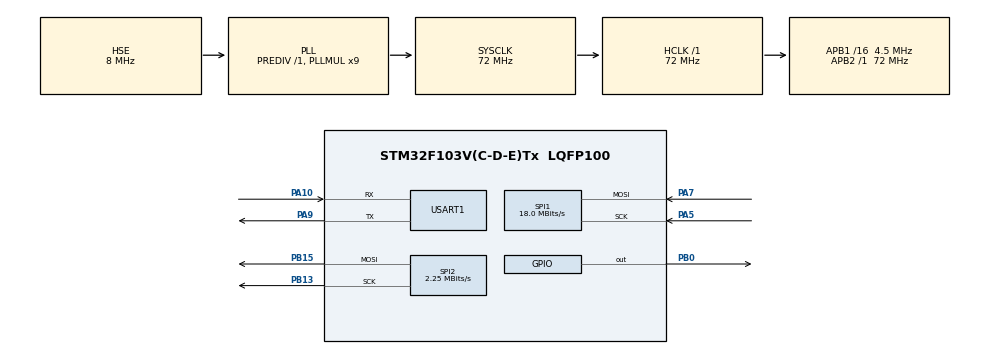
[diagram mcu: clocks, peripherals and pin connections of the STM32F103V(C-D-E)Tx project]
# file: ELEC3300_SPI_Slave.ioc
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Mcu.Family=STM32F1
Mcu.Name=STM32F103V(C-D-E)Tx
Mcu.Package=LQFP100
NVIC.PriorityGroup=NVIC_PRIORITYGROUP_4
OSC_IN.Mode=HSE-External-Oscillator
OSC_IN.Signal=RCC_OSC_IN
OSC_OUT.Mode=HSE-External-Oscillator
OSC_OUT.Signal=RCC_OSC_OUT
PA10.Mode=Asynchronous
PA10.Signal=USART1_RX
PA13.Mode=Serial_Wire
PA13.Signal=SYS_JTMS-SWDIO
PA14.Mode=Serial_Wire
PA14.Signal=SYS_JTCK-SWCLK
PA5.Mode=RX_Only_Simplex_Unidirect_Slave
PA5.Signal=SPI1_SCK
PA7.Mode=RX_Only_Simplex_Unidirect_Slave
PA7.Signal=SPI1_MOSI
PA9.Mode=Asynchronous
PA9.Signal=USART1_TX
PB0.GPIO_Speed=GPIO_SPEED_FREQ_HIGH
PB0.PinState=GPIO_PIN_SET
PB0.Signal=GPIO_Output
PB13.Mode=TX_Only_Simplex_Unidirect_Master
PB13.Signal=SPI2_SCK
PB15.Mode=TX_Only_Simplex_Unidirect_Master
PB15.Signal=SPI2_MOSI
PC14-OSC32_IN.Mode=LSE-External-Oscillator
PC14-OSC32_IN.Signal=RCC_OSC32_IN
PC15-OSC32_OUT.Mode=LSE-External-Oscillator
PC15-OSC32_OUT.Signal=RCC_OSC32_OUT
ProjectManager.HeapSize=0x200
ProjectManager.StackSize=0x400
ProjectManager.TargetToolchain=MDK-ARM V5.27
RCC.AHBFreq_Value=72000000
RCC.APB1CLKDivider=RCC_HCLK_DIV16
RCC.APB1Freq_Value=4500000
RCC.APB1TimFreq_Value=9000000
RCC.APB2Freq_Value=72000000
RCC.APB2TimFreq_Value=72000000
RCC.HCLKFreq_Value=72000000
RCC.PLLMUL=RCC_PLL_MUL9
RCC.PLLSourceVirtual=RCC_PLLSOURCE_HSE
RCC.SYSCLKFreq_VALUE=72000000
RCC.SYSCLKSource=RCC_SYSCLKSOURCE_PLLCLK
RCC.USBFreq_Value=72000000
SPI1.BaudRatePrescaler=SPI_BAUDRATEPRESCALER_4
SPI1.CalculateBaudRate=18.0 MBits/s
SPI1.Direction=SPI_DIRECTION_2LINES_RXONLY
SPI1.Mode=SPI_MODE_SLAVE
SPI1.VirtualType=VM_SLAVE
SPI2.CalculateBaudRate=2.25 MBits/s
SPI2.Direction=SPI_DIRECTION_2LINES
SPI2.Mode=SPI_MODE_MASTER
SPI2.VirtualType=VM_MASTER
USART1.VirtualMode=VM_ASYNC
board=custom

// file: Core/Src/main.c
/* USER CODE BEGIN Header */
/**
  ******************************************************************************
  * @file           : main.c
  * @brief          : Main program body
  ******************************************************************************
  * @attention
  *
  * <h2><center>&copy; Copyright (c) 2023 STMicroelectronics.
  * All rights reserved.</center></h2>
  *
  * This software component is licensed by ST under BSD 3-Clause license,
  * the "License"; You may not use this file except in compliance with the
  * License. You may obtain a copy of the License at:
  *                        opensource.org/licenses/BSD-3-Clause
  *
  ******************************************************************************
  */
/* USER CODE END Header */
#include "main.h"

SPI_HandleTypeDef hspi1;
SPI_HandleTypeDef hspi2;

UART_HandleTypeDef huart1;

void SystemClock_Config(void);
static void MX_GPIO_Init(void);
static void MX_SPI1_Init(void);
static void MX_USART1_UART_Init(void);
static void MX_SPI2_Init(void);

int main(void)
{
  /* USER CODE BEGIN 1 */
	uint8_t message_1[50] = "Now transmitting message back to NUCLEO-144\n";
	uint8_t data[27] = "ello World\n";
	uint8_t RX_Data[27] = {0};
  /* USER CODE END 1 */

  /* MCU Configuration--------------------------------------------------------*/

  /* Reset of all peripherals, Initializes the Flash interface and the Systick. */
  HAL_Init();

  /* Configure the system clock */
  SystemClock_Config();

  /* Initialize all configured peripherals */
  MX_GPIO_Init();
  MX_SPI1_Init();
  MX_USART1_UART_Init();
  MX_SPI2_Init();

  /* Infinite loop */
  while (1)
  {

    /* USER CODE BEGIN 3 */
		// Re-initialise rx_data every loop
		// We will receive data of 27 bytes (change this according to the data size being sent to slave)
		//uint8_t rx_data[27] = "No data received\n";
		//HAL_GPIO_WritePin(GPIOB, GPIO_PIN_0, GPIO_PIN_RESET);
		//HAL_Delay(100);
		//HAL_GPIO_WritePin(GPIOB, GPIO_PIN_0, GPIO_PIN_SET);
		//HAL_Delay(100);
		HAL_SPI_Transmit(&hspi2, data, 27, 5000);
		//HAL_Delay(5000);
		HAL_SPI_Receive(&hspi1, RX_Data, 27, 5000); // timing out -> if LED blink then wait for 5 secs, means receive nothing
		//HAL_Delay(5000);
		HAL_UART_Transmit(&huart1, RX_Data, 27, 5000);
		//HAL_Delay(1000);

  }
  /* USER CODE END 3 */
}

void SystemClock_Config(void)
{
  RCC_OscInitTypeDef RCC_OscInitStruct = {0};
  RCC_ClkInitTypeDef RCC_ClkInitStruct = {0};

  /** Initializes the RCC Oscillators according to the specified parameters
  * in the RCC_OscInitTypeDef structure.
  */
  RCC_OscInitStruct.OscillatorType = RCC_OSCILLATORTYPE_HSE;
  RCC_OscInitStruct.HSEState = RCC_HSE_ON;
  RCC_OscInitStruct.HSEPredivValue = RCC_HSE_PREDIV_DIV1;
  RCC_OscInitStruct.HSIState = RCC_HSI_ON;
  RCC_OscInitStruct.PLL.PLLState = RCC_PLL_ON;
  RCC_OscInitStruct.PLL.PLLSource = RCC_PLLSOURCE_HSE;
  RCC_OscInitStruct.PLL.PLLMUL = RCC_PLL_MUL9;
  if (HAL_RCC_OscConfig(&RCC_OscInitStruct) != HAL_OK)
  {
    Error_Handler();
  }
  /** Initializes the CPU, AHB and APB buses clocks
  */
  RCC_ClkInitStruct.ClockType = RCC_CLOCKTYPE_HCLK|RCC_CLOCKTYPE_SYSCLK
                              |RCC_CLOCKTYPE_PCLK1|RCC_CLOCKTYPE_PCLK2;
  RCC_ClkInitStruct.SYSCLKSource = RCC_SYSCLKSOURCE_PLLCLK;
  RCC_ClkInitStruct.AHBCLKDivider = RCC_SYSCLK_DIV1;
  RCC_ClkInitStruct.APB1CLKDivider = RCC_HCLK_DIV16;
  RCC_ClkInitStruct.APB2CLKDivider = RCC_HCLK_DIV1;

  if (HAL_RCC_ClockConfig(&RCC_ClkInitStruct, FLASH_LATENCY_2) != HAL_OK)
  {
    Error_Handler();
  }
}

static void MX_SPI1_Init(void)
{

  /* SPI1 parameter configuration*/
  hspi1.Instance = SPI1;
  hspi1.Init.Mode = SPI_MODE_SLAVE;
  hspi1.Init.Direction = SPI_DIRECTION_2LINES_RXONLY;
  hspi1.Init.DataSize = SPI_DATASIZE_8BIT;
  hspi1.Init.CLKPolarity = SPI_POLARITY_LOW;
  hspi1.Init.CLKPhase = SPI_PHASE_1EDGE;
  hspi1.Init.NSS = SPI_NSS_SOFT;
  hspi1.Init.BaudRatePrescaler = SPI_BAUDRATEPRESCALER_4;
  hspi1.Init.FirstBit = SPI_FIRSTBIT_MSB;
  hspi1.Init.TIMode = SPI_TIMODE_DISABLE;
  hspi1.Init.CRCCalculation = SPI_CRCCALCULATION_DISABLE;
  hspi1.Init.CRCPolynomial = 10;
  if (HAL_SPI_Init(&hspi1) != HAL_OK)
  {
    Error_Handler();
  }

}

static void MX_SPI2_Init(void)
{

  /* SPI2 parameter configuration*/
  hspi2.Instance = SPI2;
  hspi2.Init.Mode = SPI_MODE_MASTER;
  hspi2.Init.Direction = SPI_DIRECTION_2LINES;
  hspi2.Init.DataSize = SPI_DATASIZE_8BIT;
  hspi2.Init.CLKPolarity = SPI_POLARITY_LOW;
  hspi2.Init.CLKPhase = SPI_PHASE_1EDGE;
  hspi2.Init.NSS = SPI_NSS_SOFT;
  hspi2.Init.BaudRatePrescaler = SPI_BAUDRATEPRESCALER_2;
  hspi2.Init.FirstBit = SPI_FIRSTBIT_MSB;
  hspi2.Init.TIMode = SPI_TIMODE_DISABLE;
  hspi2.Init.CRCCalculation = SPI_CRCCALCULATION_DISABLE;
  hspi2.Init.CRCPolynomial = 10;
  if (HAL_SPI_Init(&hspi2) != HAL_OK)
  {
    Error_Handler();
  }

}

static void MX_USART1_UART_Init(void)
{

  huart1.Instance = USART1;
  huart1.Init.BaudRate = 115200;
  huart1.Init.WordLength = UART_WORDLENGTH_8B;
  huart1.Init.StopBits = UART_STOPBITS_1;
  huart1.Init.Parity = UART_PARITY_NONE;
  huart1.Init.Mode = UART_MODE_TX_RX;
  huart1.Init.HwFlowCtl = UART_HWCONTROL_NONE;
  huart1.Init.OverSampling = UART_OVERSAMPLING_16;
  if (HAL_UART_Init(&huart1) != HAL_OK)
  {
    Error_Handler();
  }

}

static void MX_GPIO_Init(void)
{
  GPIO_InitTypeDef GPIO_InitStruct = {0};

  /* GPIO Ports Clock Enable */
  __HAL_RCC_GPIOC_CLK_ENABLE();
  __HAL_RCC_GPIOA_CLK_ENABLE();
  __HAL_RCC_GPIOB_CLK_ENABLE();

  /*Configure GPIO pin Output Level */
  HAL_GPIO_WritePin(GPIOB, GPIO_PIN_0, GPIO_PIN_SET);

  /*Configure GPIO pin : PB0 */
  GPIO_InitStruct.Pin = GPIO_PIN_0;
  GPIO_InitStruct.Mode = GPIO_MODE_OUTPUT_PP;
  GPIO_InitStruct.Pull = GPIO_NOPULL;
  GPIO_InitStruct.Speed = GPIO_SPEED_FREQ_HIGH;
  HAL_GPIO_Init(GPIOB, &GPIO_InitStruct);

}

void Error_Handler(void)
{
  __disable_irq();
  while (1)
  {
  }
}

/************************ (C) COPYRIGHT STMicroelectronics *****END OF FILE****/
